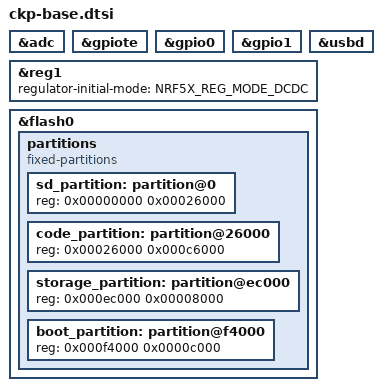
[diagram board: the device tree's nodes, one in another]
&adc {
    status = "okay";
};

&gpiote {
    status = "okay";
};

&gpio0 {
    status = "okay";
};

&gpio1 {
    status = "okay";
};

zephyr_udc0: &usbd {
    status = "okay";
};

&reg1 {
    regulator-initial-mode = <NRF5X_REG_MODE_DCDC>;
};


&flash0 {
    /*
     * For more information, see:
     * http://docs.zephyrproject.org/latest/devices/dts/flash_partitions.html
     */
    partitions {
        compatible = "fixed-partitions";
        #address-cells = <1>;
        #size-cells = <1>;

        sd_partition: partition@0 {
            reg = <0x00000000 0x00026000>;
        };
        code_partition: partition@26000 {
            reg = <0x00026000 0x000c6000>;
        };

        /*
         * The flash starting at 0x000ec000 and ending at
         * 0x000f3fff is reserved for use by the application.
         */

        /*
         * Storage partition will be used by FCB/LittleFS/NVS
         * if enabled.
         */
        storage_partition: partition@ec000 {
            reg = <0x000ec000 0x00008000>;
        };

        boot_partition: partition@f4000 {
            reg = <0x000f4000 0x0000c000>;
        };
    };
};

